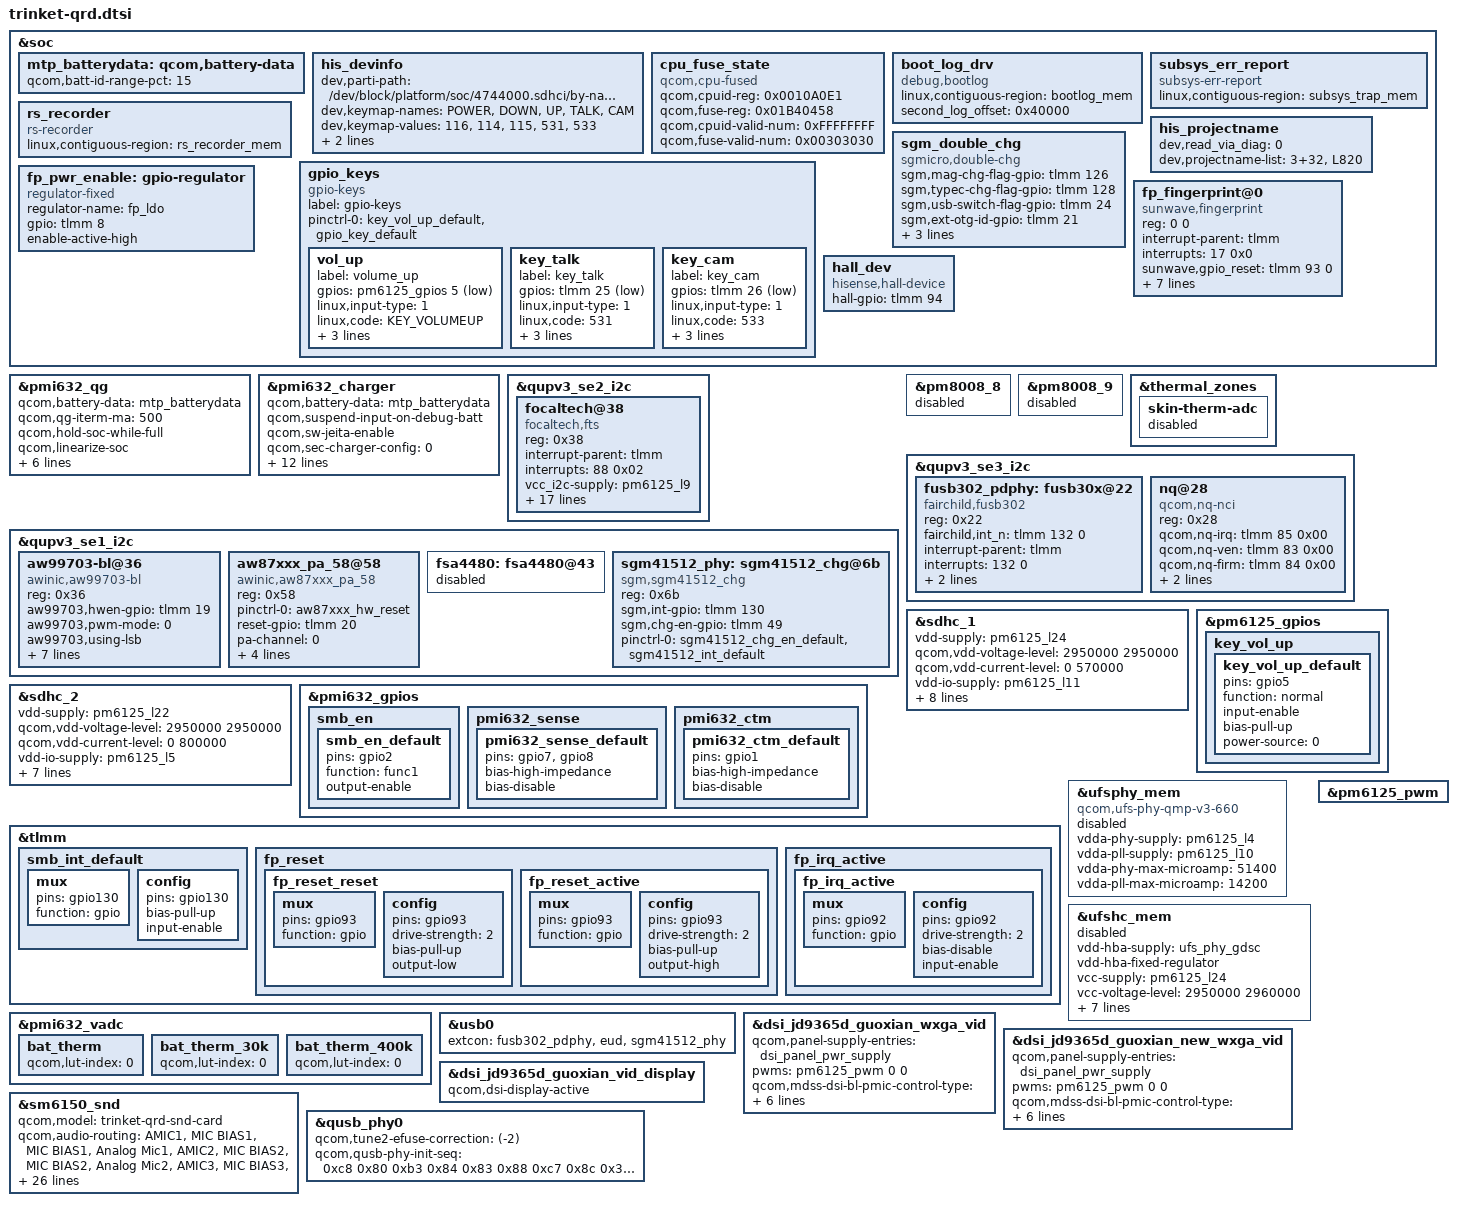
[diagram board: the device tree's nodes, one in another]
/*
 * Copyright (c) 2019, The Linux Foundation. All rights reserved.
 *
 * This program is free software; you can redistribute it and/or modify
 * it under the terms of the GNU General Public License version 2 and
 * only version 2 as published by the Free Software Foundation.
 *
 * This program is distributed in the hope that it will be useful,
 * but WITHOUT ANY WARRANTY; without even the implied warranty of
 * MERCHANTABILITY or FITNESS FOR A PARTICULAR PURPOSE.  See the
 * GNU General Public License for more details.
 */
#include <dt-bindings/gpio/gpio.h>
#include <dt-bindings/iio/qcom,spmi-vadc.h>
#include <dt-bindings/input/input.h>
#include "trinket-thermal-overlay.dtsi"
#include "trinket-sde-display.dtsi"
#include "trinket-audio-overlay.dtsi"
#include <dt-bindings/clock/qcom,gcc-trinket.h>

#include <dt-bindings/clock/qcom,gcc-trinket.h>
#include "trinket-camera-sensor-qrd.dtsi"
#include "trinket-pinctrl-overlay.dtsi"

&soc {
	mtp_batterydata: qcom,battery-data {
		qcom,batt-id-range-pct = <15>;
		#include "Hisense_l820_4820mAH_PMI632_averaged_MasterSlave_May17th2021.dtsi"		
	};

	his_devinfo {
		status = "okay";

		dev,parti-path = "/dev/block/platform/soc/4744000.sdhci/by-name/";
		/* The number of name and value MUST be same */
		dev,keymap-names = "POWER", "DOWN", "UP","TALK","CAM";
		dev,keymap-values = <116>, <114>, <115>,<531>,<533>;
		dev,prot-gpios = <0 1 2 3 22 23 28 29 30 31 32 33>;
	};

    cpu_fuse_state {
    	compatible = "qcom,cpu-fused";
    	qcom,cpuid-reg = <0x0010A0E1>;
    	qcom,fuse-reg = <0x01B40458>;                                                                                                                            
    	qcom,cpuid-valid-num = <0xFFFFFFFF>;
    	qcom,fuse-valid-num = <0x00303030>;
    	status = "okay";
	};

	boot_log_drv {
		compatible = "debug,bootlog";
		linux,contiguous-region = <&bootlog_mem>;
		second_log_offset = <0x40000>;
		status = "okay";
	};

	subsys_err_report {
		compatible = "subsys-err-report";
		linux,contiguous-region = <&subsys_trap_mem>;
		status = "okay";
	};

	rs_recorder {
		compatible = "rs-recorder";
		linux,contiguous-region = <&rs_recorder_mem>;
		status = "okay";
	};

      his_projectname {
		status = "okay";
		dev,read_via_diag = <0>;
		dev,projectname-list =
			"3+32",   "L820";
	};

	/*** BSP : hmct add for ext-pin-connector, Magconn@{ */
	sgm_double_chg {
		compatible = "sgmicro,double-chg";
		sgm,mag-chg-flag-gpio = <&tlmm 126 0>;
		sgm,typec-chg-flag-gpio = <&tlmm 128 0>;
		sgm,usb-switch-flag-gpio = <&tlmm 24 0>;
		sgm,ext-otg-id-gpio = <&tlmm 21 0>;
		pinctrl-names = "default";
		pinctrl-0 = <&mag_chg_flag_default &typec_chg_flag_default
					&usb_switch_flag_default &ext_otg_id_default>;
		status = "okay";
	};
	/*** @} */
};

&pmi632_qg {
	qcom,battery-data = <&mtp_batterydata>;
	qcom,qg-iterm-ma = <500>;
	qcom,hold-soc-while-full;
	qcom,linearize-soc;
	qcom,qg-use-s7-ocv;
	qcom,vbatt-cutoff-mv = <3350>;
	qcom,vbatt-low-mv = <3450>;
	qcom,vbatt-low-cold-mv = <3750>;
	qcom,vbatt-empty-mv = <3250>;
	qcom,vbatt-empty-cold-mv = <3250>;
};

&pmi632_charger {
	qcom,battery-data = <&mtp_batterydata>;
	qcom,suspend-input-on-debug-batt;
	qcom,sw-jeita-enable;
	/*Do not support second charger*/
	qcom,sec-charger-config = <0>;
	dpdm-supply = <&qusb_phy0>;
	qcom,usb-icl-ua = <2000000>;
	qcom,float-icl-ua = <900000>;
	qcom,hvdcp-disable;
	qcom,charger-temp-max = <800>;
	qcom,smb-temp-max = <800>;
	qcom,auto-recharge-soc = <98>;
	qcom,hw-die-temp-mitigation;
	qcom,connector-internal-pull-kohm = <100>;
	qcom,float-option = <1>;
	qcom,thermal-mitigation = <2000000 2000000 2000000
			2000000 2000000 2000000 2000000 2000000>;
};

&qupv3_se2_i2c {
	status = "okay";

	focaltech@38{
		compatible = "focaltech,fts";
		reg = <0x38>;
		interrupt-parent = <&tlmm>;
		interrupts = <88 0x02>;
		vcc_i2c-supply = <&pm6125_l9>;
		focaltech,vdd-gpio = <&tlmm 43 0x1>;
		focaltech,reset-gpio = <&tlmm 87 0x01>;
		focaltech,irq-gpio = <&tlmm 88 0x02>;
		focaltech,max-touch-number = <8>;
		focaltech,display-coords =  <0 0 800 1280>;
		pinctrl-names = "pmx_ts_active","pmx_ts_suspend","pmx_ts_release";
		pinctrl-0 = <&ts_int_active &ts_reset_active>;
		pinctrl-1 = <&ts_int_suspend &ts_reset_suspend>;
		pinctrl-2 = <&ts_release>;

		/*
		focaltech,have-key;
		focaltech,key-number = <3>;
		focaltech,keys = <139 102 158>;
		focaltech,key-x-coords = <200 600 800>;
		focaltech,key-y-coords = <2000 2000 2000>;
		*/
		focaltech,factory-info = "ft5xx6";
		focaltech,name = "focaltech";
		focaltech,fw-name = "fw_ft5xx6_0xFF.bin";
		panel = <&dsi_jd9365d_guoxian_wxga_vid &dsi_jd9365d_guoxian_new_wxga_vid>;
		focaltech,gesture-func-map = <509 510 511 512 513 514 515 516 520 519>;
		focaltech,gesture-figure-map = <0x24 0x52 0x51 0x30 0x54 0x31 0x46 0x41 0x32 0x33>;//double tap,>,c,o,v,w,s,z,m,e
	};

};

&qupv3_se1_i2c {
	status = "ok";

 	aw99703-bl@36 {
		compatible = "awinic,aw99703-bl";
		reg = <0x36>;
 		pinctrl-names = "default";
 		aw99703,hwen-gpio = <&tlmm 19 0>;
 		aw99703,pwm-mode = <0>;  /*0 pwm disable,1 PWM enable*/
 		aw99703,using-lsb;
 		aw99703,bl-fscal-led = <0x13>;/*20mA*/
 		aw99703,turn-on-ramp = <0x0>;
		aw99703,turn-off-ramp = <0x0>;
 		aw99703,pwm-trans-dim = <0>;
 		aw99703,i2c-trans-dim = <0x00>;//default 1us/step
		aw99703,bl-channel = <3>;
 		aw99703,bl-map = <3>; /*brightness map level 1:256,2:1024,3:2048*/
 	};

	aw87xxx_pa_58@58 {
			compatible = "awinic,aw87xxx_pa_58";
			reg = <0x58>;
			pinctrl-names = "default";
			pinctrl-0 = <&aw87xxx_hw_reset>;		
			reset-gpio = <&tlmm 20 0>;
			pa-channel = < 0 >;
			/* actflag-gain-array: off music voice fm rcv */
			actflag-gain-array = < 0x00 0x08 0x08 0x08 0x00 >;
			/*actflag-auto-run;*/
			monitor-flag = <1>;
			monitor-timer-val = <3000>;
			monitor-timer-count-max = <5>;
			status = "okay";
		};	 

	fsa4480: fsa4480@43 {
		status = "disabled";
	};
	/*** @} */

	/*-[START]- Added by HMCT for second charger ic.*/
	sgm41512_phy: sgm41512_chg@6b {
		compatible = "sgm,sgm41512_chg";
		reg = <0x6b>;
		sgm,int-gpio = <&tlmm 130 0>;
		sgm,chg-en-gpio = <&tlmm 49 0>;
		pinctrl-names = "default";
		pinctrl-0 = <&sgm41512_chg_en_default &sgm41512_int_default>;
		status = "okay";
	};
	/*-[END]-Added by HMCT for second charger ic.*/
};

&pm8008_8 {
	status = "disabled";
};

&pm8008_9 {
	status = "disabled";
};

&thermal_zones {
    skin-therm-adc {
            status = "disabled";
    };
};

&qupv3_se3_i2c {
	status = "ok";

	/*** BSP : hmct add for third-party PD chip fusb302.@{ */
	fusb302_pdphy: fusb30x@22{
		compatible = "fairchild,fusb302";
		reg = <0x22>;
		status = "okay";
		fairchild,int_n = <&tlmm 132 0>;
		interrupt-parent = <&tlmm>;
		interrupts = <132 0>;
		pinctrl-names = "fairchild_enable_int";
		pinctrl-0 = <&fairchild_int_gpio>;
		vbus-supply = <&smb5_vbus>;
	};
	
    nq@28 {
		status = "okay";
		compatible = "qcom,nq-nci";
		reg = <0x28>;
		qcom,nq-irq = <&tlmm 85 0x00>;
		qcom,nq-ven = <&tlmm 83 0x00>;
		qcom,nq-firm = <&tlmm 84 0x00>;
		//qcom,nq-clkreq = <&tlmm 86 0x00>;
		interrupt-parent = <&tlmm>;
		interrupts = <85 0>;
		interrupt-names = "nfc_irq";
		//pinctrl-names = "default";
		//pinctrl-0 = <&nfc_int_default>;
	};		
	
};
&sdhc_1 {
	vdd-supply = <&pm6125_l24>;
	qcom,vdd-voltage-level = <2950000 2950000>;
	qcom,vdd-current-level = <0 570000>;

	vdd-io-supply = <&pm6125_l11>;
	qcom,vdd-io-always-on;
	qcom,vdd-io-lpm-sup;
	qcom,vdd-io-voltage-level = <1800000 1800000>;
	qcom,vdd-io-current-level = <0 325000>;

	pinctrl-names = "active", "sleep";
	pinctrl-0 = <&sdc1_clk_on &sdc1_cmd_on &sdc1_data_on
					&sdc1_rclk_on>;
	pinctrl-1 = <&sdc1_clk_off &sdc1_cmd_off &sdc1_data_off
					&sdc1_rclk_off>;

	status = "ok";
};

&sdhc_2 {
	vdd-supply = <&pm6125_l22>;
	qcom,vdd-voltage-level = <2950000 2950000>;
	qcom,vdd-current-level = <0 800000>;

	vdd-io-supply = <&pm6125_l5>;
	qcom,vdd-io-voltage-level = <1800000 2950000>;
	qcom,vdd-io-current-level = <0 22000>;

	pinctrl-names = "active", "sleep";
	pinctrl-0 = <&sdc2_clk_on  &sdc2_cmd_on &sdc2_data_on &sdc2_cd_on>;
	pinctrl-1 = <&sdc2_clk_off &sdc2_cmd_off &sdc2_data_off &sdc2_cd_off>;

	cd-gpios = <&tlmm 98 GPIO_ACTIVE_HIGH>;

	status = "ok";
};

&pmi632_gpios {
	smb_en {
		smb_en_default: smb_en_default {
			pins = "gpio2";
			function = "func1";
			output-enable;
		};
	};

	pmi632_sense {
		/* GPIO 7 and 8 are external-sense pins for PMI632 */
		pmi632_sense_default: pmi632_sense_default {
			pins = "gpio7", "gpio8";
			bias-high-impedance;	/* disable the GPIO */
			bias-disable;		/* no-pull */
		};
	};

	pmi632_ctm {
		/* Disable GPIO1 for h/w base mitigation */
		pmi632_ctm_default: pmi632_ctm_default {
			pins = "gpio1";
			bias-high-impedance;	/* disable the GPIO */
			bias-disable;		/* no-pull */
		};
	};
};

&pm6125_gpios {
	key_vol_up {
		key_vol_up_default: key_vol_up_default {
			pins = "gpio5";
			function = "normal";
			input-enable;
			bias-pull-up;
			power-source = <0>;
		};
	};
};

&soc {
	gpio_keys {
		compatible = "gpio-keys";
		label = "gpio-keys";

		pinctrl-names = "default";
		pinctrl-0 = <&key_vol_up_default &gpio_key_default>;

		vol_up {
			label = "volume_up";
			gpios = <&pm6125_gpios 5 GPIO_ACTIVE_LOW>;
			linux,input-type = <1>;
			linux,code = <KEY_VOLUMEUP>;
			linux,can-disable;
			debounce-interval = <15>;
			gpio-key,wakeup;
		};

		key_talk {
			label = "key_talk";
			gpios = <&tlmm 25 GPIO_ACTIVE_LOW>;
			linux,input-type = <1>;
			linux,code = <531>;
			gpio-key,wakeup;
			debounce-interval = <15>;
			linux,can-disable;
		};
		
             key_cam {
			label = "key_cam";
			gpios = <&tlmm 26 GPIO_ACTIVE_LOW>;
			linux,input-type = <1>;
			linux,code = <533>;
			gpio-key,wakeup;
			debounce-interval = <15>;
			linux,can-disable;
		};

	};

	fp_pwr_enable: gpio-regulator {
		compatible = "regulator-fixed";
		regulator-name = "fp_ldo";
		gpio = <&tlmm 8 0>;
		enable-active-high;
	};

	fp_fingerprint@0 {
		status = "ok";
		reg = <0 0>;
		compatible = "sunwave,fingerprint";
		interrupt-parent = <&tlmm>;
		interrupts = <17 0x0>;
		sunwave,gpio_reset = <&tlmm 93 0>;
		sunwave,gpio_irq = <&tlmm 92 0>;
		sunwave,gpio_pwr = <&tlmm 8 0>;
		input-device-name = "sf-keys";
		vdd-supply = <&fp_pwr_enable>;

		pinctrl-names = "sunwave_reset_reset",
				"sunwave_reset_active",
				"sunwave_irq_active";

		pinctrl-0 = <&fp_reset_reset>;
		pinctrl-1 = <&fp_reset_active>;
		pinctrl-2 = <&fp_irq_active>;
	};

	hall_dev {
		compatible = "hisense,hall-device";
		status = "ok";
		hall-gpio = <&tlmm 94 0>;
	};
};

&tlmm {
	smb_int_default: smb_int_default {
		mux {
			pins = "gpio130";
			function = "gpio";
		};
		config {
			pins = "gpio130";
			bias-pull-up;
			input-enable;
		};
	};

	fp_reset {
		fp_reset_reset: fp_reset_reset {
			mux {
				pins = "gpio93";
				function = "gpio";
			};

			config {
				pins = "gpio93";
				drive-strength = <2>;
				bias-pull-up;
				output-low;
			};
		};
		fp_reset_active: fp_reset_active {
			mux {
				pins = "gpio93";
				function = "gpio";
			};

			config {
				pins = "gpio93";
				drive-strength = <2>;
				bias-pull-up;
				output-high;
			};
		};
	};

	fp_irq_active {
		fp_irq_active: fp_irq_active {
			mux {
				pins = "gpio92";
				function = "gpio";
			};

			config {
				pins = "gpio92";
				drive-strength = <2>;
				bias-disable;
				input-enable;
			};
		};
	};
};

&ufsphy_mem {
	compatible = "qcom,ufs-phy-qmp-v3-660";

	vdda-phy-supply = <&pm6125_l4>; /* 0.9v */
	vdda-pll-supply = <&pm6125_l10>; /* 1.8v */
	vdda-phy-max-microamp = <51400>;
	vdda-pll-max-microamp = <14200>;

	status = "disabled";
};

&ufshc_mem {
	vdd-hba-supply = <&ufs_phy_gdsc>;
	vdd-hba-fixed-regulator;
	vcc-supply = <&pm6125_l24>;
	vcc-voltage-level = <2950000 2960000>;
	vccq2-supply = <&pm6125_l11>;
	vcc-max-microamp = <600000>;
	vccq2-max-microamp = <600000>;

	qcom,vddp-ref-clk-supply = <&pm6125_l18>;
	qcom,vddp-ref-clk-max-microamp = <100>;
	qcom,vddp-ref-clk-min-uV = <1200000>;
	qcom,vddp-ref-clk-max-uV = <1232000>;

	status = "disabled";
};

&pmi632_vadc {
	bat_therm {
		qcom,lut-index = <0>;
	};

	bat_therm_30k {
		qcom,lut-index = <0>;
	};

	bat_therm_400k {
		qcom,lut-index = <0>;
	};
};

&usb0 {
	extcon = <&fusb302_pdphy>, <&eud>, <&sgm41512_phy>;
};

&dsi_jd9365d_guoxian_wxga_vid {
	qcom,panel-supply-entries = <&dsi_panel_pwr_supply>;
	pwms = <&pm6125_pwm 0 0>;
	//qcom,bl-pmic-pwm-period-usecs = <100>;
	qcom,mdss-dsi-bl-pmic-control-type = "bl_ctrl_external";
	qcom,mdss-dsi-bl-min-level = <1>;
	qcom,mdss-dsi-bl-max-level = <2047>;
	qcom,mdss-dsi-bl-default-level = <614>;
	qcom,platform-reset-gpio = <&tlmm 90 0>;
	qcom,platform-1v8en-gpio = <&tlmm 45 0>;
};

&dsi_jd9365d_guoxian_new_wxga_vid {
	qcom,panel-supply-entries = <&dsi_panel_pwr_supply>;
	pwms = <&pm6125_pwm 0 0>;
	//qcom,bl-pmic-pwm-period-usecs = <100>;
	qcom,mdss-dsi-bl-pmic-control-type = "bl_ctrl_external";
	qcom,mdss-dsi-bl-min-level = <1>;
	qcom,mdss-dsi-bl-max-level = <2047>;
	qcom,mdss-dsi-bl-default-level = <614>;
	qcom,platform-reset-gpio = <&tlmm 90 0>;
	qcom,platform-1v8en-gpio = <&tlmm 45 0>;
};

&dsi_jd9365d_guoxian_vid_display {
	qcom,dsi-display-active;
};

&pm6125_pwm {
	status = "ok";
};

&sm6150_snd {
	status = "okay";
	qcom,model = "trinket-qrd-snd-card";
	qcom,audio-routing =
		"AMIC1", "MIC BIAS1",
		"MIC BIAS1", "Analog Mic1",
		"AMIC2", "MIC BIAS2",
		"MIC BIAS2", "Analog Mic2",
		"AMIC3", "MIC BIAS3",
		"MIC BIAS3", "Analog Mic3",
		"TX_AIF1 CAP", "VA_MCLK",
		"TX_AIF2 CAP", "VA_MCLK",
		"RX AIF1 PB", "VA_MCLK",
		"RX AIF2 PB", "VA_MCLK",
		"RX AIF3 PB", "VA_MCLK",
		"RX AIF4 PB", "VA_MCLK",
		"HPHL_OUT", "VA_MCLK",
		"HPHR_OUT", "VA_MCLK",
		"AUX_OUT", "VA_MCLK",
		"IN1_HPHL", "HPHL_OUT",
		"IN2_HPHR", "HPHR_OUT",
		"IN3_AUX", "AUX_OUT",
		"TX SWR_ADC0", "ADC1_OUTPUT",
		"TX SWR_ADC2", "ADC2_OUTPUT",
		"WSA SRC0_INP", "SRC0",
		"WSA_TX DEC0_INP", "TX DEC0 MUX",
		"WSA_TX DEC1_INP", "TX DEC1 MUX",
		"RX_TX DEC0_INP", "TX DEC0 MUX",
		"RX_TX DEC1_INP", "TX DEC1 MUX",
		"RX_TX DEC2_INP", "TX DEC2 MUX",
		"RX_TX DEC3_INP", "TX DEC3 MUX",
		"SpkrLeft IN", "WSA_SPK1 OUT",
		"WSA_SPK1 OUT", "VA_MCLK";
		qcom,wsa-max-devs = <0>;
		
		qcom,wsa-aux-dev-prefix = "SpkrLeft", "SpkrLeft";
		qcom,msm-mbhc-hphl-swh = <1>;
		qcom,msm-mbhc-gnd-swh = <1>;
		asoc-codec  = <&stub_codec>, <&bolero>, <&ext_disp_audio_codec>;
		asoc-codec-names = "msm-stub-codec.1", "bolero_codec",
				   "msm-ext-disp-audio-codec-rx";
		qcom,codec-max-aux-devs = <1>;
		qcom,codec-aux-devs = <&wcd937x_codec>;
		qcom,msm_audio_ssr_devs = <&audio_apr>, <&q6core>,
				<&bolero>;
};

&qusb_phy0 {
	qcom,tune2-efuse-correction = <(-2)>;
	qcom,qusb-phy-init-seq = <0xc8 0x80
				0xb3 0x84
				0x83 0x88
				0xc7 0x8c
				0x30 0x08
				0x79 0x0c
				0x21 0x10
				0x14 0x9c
				0x80 0x04
				0x9f 0x1c
				0x00 0x18>;
};
